# SPINLOCK register map
Vendor: Texas Instruments
Peripheral module from a debugger description file (folder am335x).
Registers are 32-bit, access per field, no defined reset value unless marked. A register's access mark holds for its fields unless they carry their own. Offsets are as the file gives them; lines under a group give offsets from that group; [hi:lo] are bit positions; {n}, {i} and the like mark numbered series; 'fields as' and 'values as' point back to an identical list; <NAME> marks a mode.

## SPINLOCK
0x00 REV ro — Read-only IP revision identifier (X.Y.R) used by software to determine features, bugs and compatibility of an instance of this the Spin Lock module.
  [31:0] REV — IP Revision Code.
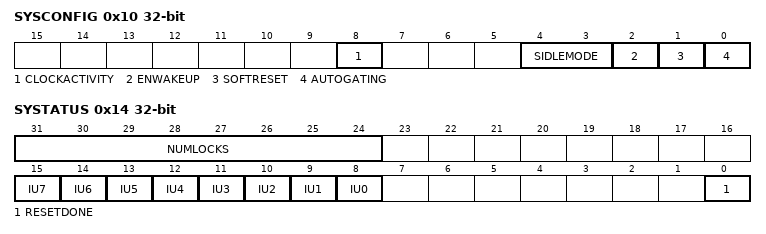
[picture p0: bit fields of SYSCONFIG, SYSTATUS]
0x10 SYSCONFIG — This register controls the various parameters of the OCP interface. Note that several fields are present by read-only.
  [8] CLOCKACTIVITY ro — Indicates whether the module requires the OCP when in IDLE mode.
    0=NOTREQUIRED (OCP clock is not required by the module during IDLE mode and may be switched off.); 1=REQUIRED (OCP clock is required by the module, even during idle mode.)
  [4:3] SIDLEMODE ro — Control of the slave interface power management IDLE request acknowledgement.
    0=FORCEIDLE (IDLE request is acknowledged unconditionally and immediately.); 1=NOIDLE (IDLE request is never acknowledged.); 2=SMARTIDLE (IDLE request acknowledgement is based on the internal module activity.)
  [2] ENWAKEUP ro — Asynchronous wakeup gereration.
    0=NOWAKEUPGEN (Wakeup generation is disabled.); 1=WAKEUPGEN1 (Enable wakeup generation.)
  [1] SOFTRESET wo — Module software reset.
    0=NOOP; 1=DORESET (Start a soft reset sequence of the Spin Lock module.)
  [0] AUTOGATING ro — Internal OCP clock gating strategy.
    0=FREERUNNING (OCP clock is not gated when OCP interface is idle.); 1=GATED (Automatic internal OCP clock gating strategy is applied, based on the OCP interface activity.)
0x14 SYSTATUS ro — This register provides status information about this instance of the Spin Lock module.
  [31:24] NUMLOCKS
    1=32LOCKS (This instance has 32 lock registers.); 2=64LOCKS (This instance has 64 lock registers.); 4=128LOCKS (This instance has 128 lock registers.); 8=256LOCKS (This instance has 256 lock registers.)
  [n+8] IU{n} (n=2..7)
  [9] IU1 — In-Use flag 1, covering lock registers 32 - 63. Reads as one only if one or more lock registers in this range are TAKEN. If no lock registers are implemented in this range, then this flag always reads as 0.
  [8] IU0 — In-Use flag 0, covering lock registers 0 - 31. Reads as one only if one or more lock registers in this range are TAKEN.
  [0] RESETDONE — 0: Reset in progress. 1: Reset is completed.
{0x800+4i} LOCK_REG_{i} (i=0..31) — This register is read when attempting to acquire a lock. The lock is automatically taken if it was not taken and the value returned by the read is zero. If the lock was already taken, then the read returns one. Writing a zero to this register frees the lock.
  [0] TAKEN rw
    0=FREE (On a read, indicates that the lock was previously free. On a write, sets the lock to not taken (free).); 1=BUSY (On a read, indicates that the lock was already taken (busy). Writes of BUSY are ignored.)
